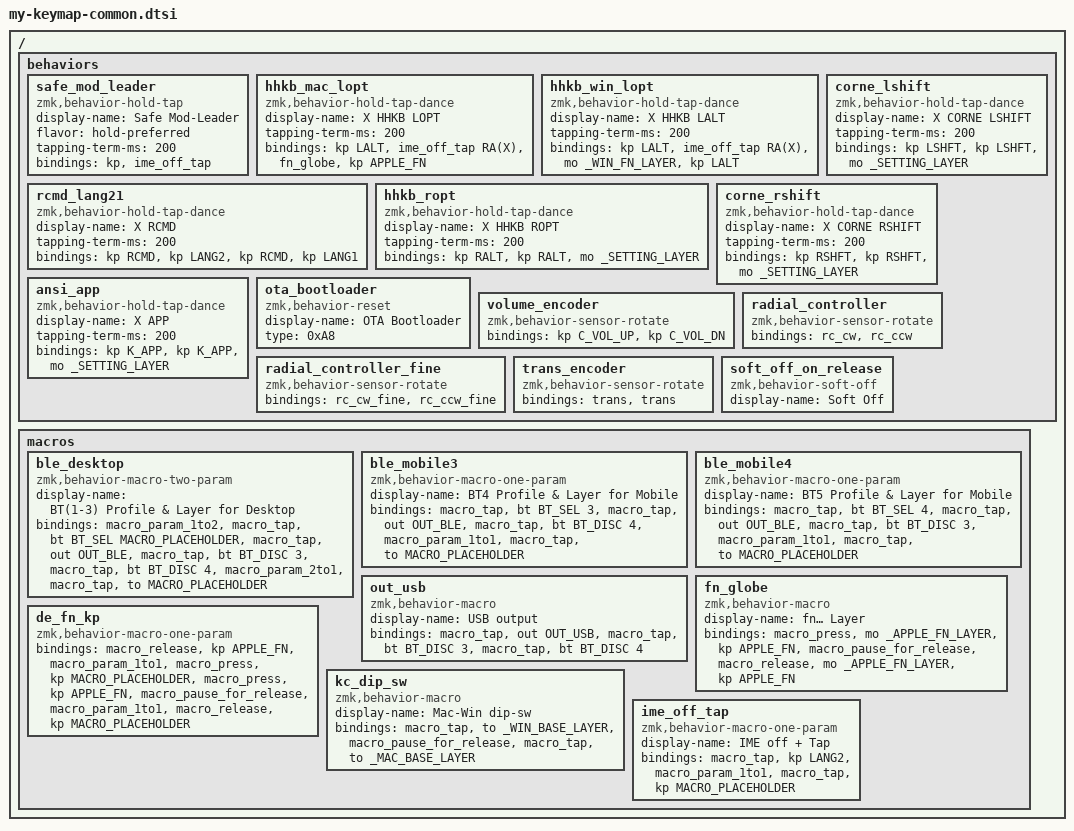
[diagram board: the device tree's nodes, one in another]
#include <behaviors.dtsi>
#include <behaviors/radial_controller.dtsi>
#include <behaviors/beep.dtsi>
#include <dt-bindings/zmk/keys.h>
#include <dt-bindings/zmk/extra_keys.h>
#include <dt-bindings/zmk/outputs.h>
#include <dt-bindings/zmk/bt.h>
#include <dt-bindings/zmk/rgb.h>
#include <dt-bindings/zmk/ext_power.h>
#include <dt-bindings/zmk/beep.h>

#define ______ &trans

// extra key
//--------------------------------------------

// keyboard Page F16
#undef F16
#define F16 EXTRA_KEY_0

// keyboard Page F17
#undef F17
#define F17 EXTRA_KEY_1

// keyboard Page F18
#undef F18
#define F18 EXTRA_KEY_2

// keyboard Page LANG1
#undef LANG1
#define LANG1 EXTRA_KEY_3

// keyboard Page LANG2
#undef LANG2
#define LANG2 EXTRA_KEY_4

// AVT Page keyboardFn
#define APPLE_FN EXTRA_KEY_5

// System Control Page Do Not Disturb
#define SC_DND EXTRA_KEY_6

// common layers
//--------------------------------------------

#define _MAC_BASE_LAYER 0
#define _WIN_BASE_LAYER 1
#define _HHKB_FN_LAYER 2
#define _APPLE_FN_LAYER 3
#define _WIN_FN_LAYER 4
#define _SETTING_LAYER 5
#define _INVERSE_SETTING_LAYER 6
#define _L_THUMB_LAYER 7
#define _R_THUMB_LAYER 8

// key definitions other than kp/trans behavior
//--------------------------------------------

// mod + emacs commands leader key
// hold   mod
// single tap emacs command leader key
#define _MOD_EMACS(mod) &safe_mod_leader mod RA(X)

// mod + spacemacs evil leader key
// hold   mod
// single tap spacemacs leader key
#define _MOD_EVIL(mod) &safe_mod_leader mod RA(M)

// keychron DIP SW
// off: mac base layer
// on: win base layer
#define _DIP_SW &kc_dip_sw

// select mac base layer
#define _MAC &to _MAC_BASE_LAYER

// select win base layer
#define _WIN &to _WIN_BASE_LAYER

// Left Opt on mac base layer for HHKB layout
#define _H_M_LOPT &hhkb_mac_lopt

// Left Opt on mac base layer for HHKB layout
#define _H_W_LOPT &hhkb_win_lopt

// Left Command
#define _LCMD _MOD_EVIL(LCMD)

// Left Opt
#define _LOPT _MOD_EMACS(LALT)

// Right Command
#define _RCMD &rcmd_lang21

// Right Opt for HHKB layout
#define _H_ROPT &hhkb_ropt

// Right Shift for corne keyboard
#define _C_LSHFT &corne_lshift

// Right Shift for corne keyboard
#define _C_RSHFT &corne_rshift

// Left Enter for corne keyboard
// hold: Momentaly L Thumb layer
// tap: ENTER
#define _C_LENT &lt _L_THUMB_LAYER ENTER

// Right SPACE for corne keyboard
// hold: Momentaly R Thumb layer
// tap: ENTER
#define _C_RSPC &lt _R_THUMB_LAYER SPC

// HHKB fn
#define _H_FN &mo _HHKB_FN_LAYER

// Fn/Globe key with momnetary Apple Fn Layer
#define _A_FN &fn_globe

// Fn/Globe key on win base layer
#define _W_FN &mo _WIN_FN_LAYER

// Fn/Globe key on win base layer
#define _X_SET &mo _INVERSE_SETTING_LAYER

// APP key for ANSI/TSANGAN layout
#define _APP &ansi_app

// Spotlight key on apple fn Layer
#define _SPOTLIGHT &de_fn_kp C_AC_SEARCH

// Dictation key on apple fn Layer
#define _DICTATION &de_fn_kp C_VOICE_COMMAND

// Do Not Disturb on apple fn Layer
#define _DND &de_fn_kp SC_DND

// mac power control
//--------------------------------------------
// sscreen lock / sceen saver
#define _MAC_SCLK &kp C_AL_LOCK

// display sleep
// *In sometimes, macos external display dosen't work after KVM switching
//  Press twice this key and then press any key to resolve the issue.
#define _MAC_DSLP &kp RC(RS(K_PWR))

// system sleep
#define _MAC_SSLP &kp RA(RG(K_PWR))

// system sleep or shutdown or restart
#define _MAC_SLRS &kp RC(K_PWR)

// windows power control
//--------------------------------------------
// sscreen lock / sceen saver
#define _WIN_SCLK &kp RG(L)

// soft off
//--------------------------------------------
#define _SOFT_OFF &soft_off_on_release

// ext_power
//--------------------------------------------
#define _EP_ON &ext_power EP_ON
#define _EP_OFF &ext_power EP_OFF

// underglow
//--------------------------------------------
#define _RGB_ON &rgb_ug RGB_ON
#define _RGB_OFF &rgb_ug RGB_OFF
#define _BRI &rgb_ug RGB_BRI
#define _BRD &rgb_ug RGB_BRD
#define _HUI &rgb_ug RGB_HUI
#define _HUD &rgb_ug RGB_HUD
#define _SAI &rgb_ug RGB_SAI
#define _SAD &rgb_ug RGB_SAD
#define _SPI &rgb_ug RGB_SPI
#define _SPD &rgb_ug RGB_SPD
#define _EFF &rgb_ug RGB_EFF
#define _EFR &rgb_ug RGB_EFF

// beep
//--------------------------------------------
#define _BP_ON &beep BEEP_ON
#define _BP_OFF &beep BEEP_OFF
#define _BP_PLY &beep BEEP_PLY

// ZMK STUDIO
//--------------------------------------------
#define _STUDIO &studio_unlock

// Emulate fn/globe shortcut keys for windows
//--------------------------------------------

// F1 : decrease brightness
#define _FN_F1 &kp C_BRI_DN
// F2 : decrease brightness
#define _FN_F2 &kp C_BRI_UP
// F3 : mission cntrol
#define _FN_F3 &kp RG(TAB)
// F4 : spotlight
#define _FN_F4 &kp RA(SPC)
// F5 : dictation, long press for "Hey Siri"
#define _FN_F5 &kp RG(H)
// F6 : do not disturb TODO
#define _FN_F6 &kp F6
// F7 : media prev
#define _FN_F7 &kp C_PREV
// F8 : media play/pause
#define _FN_F8 &kp C_PP
// F9 : media next
#define _FN_F9 &kp C_NEXT
// F10 : mute audio
#define _FN_F10 &kp C_MUTE
// F11 : decrease audio volume
#define _FN_F11 &kp C_VOL_DN
// F12 : increase audio volume
#define _FN_F12 &kp C_VOL_UP
// SPC : Hey Siri -> Copilot
#define _FN_SPC &kp RG(C)
// Q : Quck Notes
#define _FN_Q &kp RG(RA(N))
// E : Emoji & Symbols
#define _FN_E &kp RG(DOT)
// A : Focus Dock
#define _FN_A &kp RG(B)
// F : Full Screen Mode
#define _FN_F &kp F11
// H : Show Desktop
#define _FN_H &kp RG(COMMA)
// C : Show Control Center
#define _FN_C &kp RG(A)
// N : Show Notification
#define _FN_N &kp RG(N)
// M : Focus Menubar
#define _FN_M &kp RALT
// Backspace: Forward delete
#define _FN_BS &kp DEL
// Right : Scroll to the end of a documen
#define _FN_RIGHT &kp KC_END
// Left :  Scroll to the beginning of a document
#define _FN_LEFT &kp KC_HOME
// Down : Scroll down one page
#define _FN_DOWN &kp KC_PGDN
// UP : Scroll up one page
#define _FN_UP &kp KC_PGUP

// select output
//--------------------------------------------

#define _BT_MAC1 &ble_desktop 0 _MAC_BASE_LAYER
#define _BT_MAC2 &ble_desktop 1 _MAC_BASE_LAYER
#define _BT_WIN &ble_desktop 2 _WIN_BASE_LAYER
// for iOS
#define _BT_IOS &ble_mobile3 _MAC_BASE_LAYER
// for Android
#define _BT_AOS &ble_mobile4 _WIN_BASE_LAYER
#define _BT_OFF0 &bt BT_DISC 0
#define _BT_OFF1 &bt BT_DISC 1
#define _BT_OFF2 &bt BT_DISC 2
#define _BT_OFF3 &bt BT_DISC 3
#define _BT_OFF4 &bt BT_DISC 4
#define _BT_CLR &bt BT_CLR
#define _BT_CLR_ALL &bt BT_CLR_ALL
#define _USB &out_usb

// macro / behavior
//--------------------------------------------

/ {
  behaviors {
    // Mod-Tap with IME off
    // leader keys of most application are not work correctly when IME is on.
    /omit-if-no-ref/ safe_mod_leader: safe_mod_leader {
      display-name = "Safe Mod-Leader";
      compatible = "zmk,behavior-hold-tap";
      #binding-cells = <2>;
      flavor = "hold-preferred";
      tapping-term-ms = <200>;
      //          Mod    Tap
      bindings = <&kp>, <&ime_off_tap>;
    };

    // Left Option key on mac base layer for HHKB layout
    // hold -> Left Optoon
    // single tap ->  emacs command leader key
    // tap hold -> APPLE_FN + MO(_MAC_FN_LAYER)
    // double tap -> APPLE_FN
    /omit-if-no-ref/ hhkb_mac_lopt: hhkb_mac_lopt {
      display-name = "X HHKB LOPT";
      compatible = "zmk,behavior-hold-tap-dance";
      #binding-cells = <0>;
      tapping-term-ms = <200>;
      //          hold        tap                   tap-hold     multi-tap
      bindings = <&kp LALT>, <&ime_off_tap RA(X)>, <&fn_globe>, <&kp APPLE_FN>;
    };

    // Left Option key on win base layer for HHKB layout
    // hold -> Left Alt
    // single tap ->  emacs command leader key
    // tap hold -> MO(_WIN_FN_LAYER)
    // double tap -> Left Alt
    /omit-if-no-ref/ hhkb_win_lopt: hhkb_win_lopt {
      display-name = "X HHKB LALT";
      compatible = "zmk,behavior-hold-tap-dance";
      #binding-cells = <0>;
      tapping-term-ms = <200>;
      //          hold        tap                   tap-hold             multi-tap
      bindings = <&kp LALT>, <&ime_off_tap RA(X)>, <&mo _WIN_FN_LAYER>, <&kp LALT>;
    };

    // Right Command key
    // hold -> Right Cmd
    // single tap ->  LANG2(英数)
    // tap hold -> Right CMd
    // double tap -> LANG1(かな)
    /omit-if-no-ref/ rcmd_lang21: rcmd_lang21 {
      display-name = "X RCMD";
      compatible = "zmk,behavior-hold-tap-dance";
      #binding-cells = <0>;
      tapping-term-ms = <200>;
      //          hold       tap          tap-hold     multi-tap
      bindings = <&kp RCMD>, <&kp LANG2>, <&kp RCMD>, <&kp LANG1>;
    };

    // Right Option key for HHKB layout
    // hold -> Right Alt
    // single tap ->  Right Alt
    // tap hold -> MO(_SETTING_LAYER)
    // double tap -> Left Alt
    /omit-if-no-ref/ hhkb_ropt: hhkb_ropt {
      display-name = "X HHKB ROPT";
      compatible = "zmk,behavior-hold-tap-dance";
      #binding-cells = <0>;
      tapping-term-ms = <200>;
      //          hold        tap         tap-hold
      bindings = <&kp RALT>, <&kp RALT>, <&mo _SETTING_LAYER>;
    };

    // Left Shift key for 6c Corne layout
    // hold -> Left Shift
    // single tap ->  Left SHift
    // tap hold -> MO(_SETTING_LAYER)
    // double tap -> Left Shift
    /omit-if-no-ref/ corne_lshift: corne_lshift {
      display-name = "X CORNE LSHIFT";
      compatible = "zmk,behavior-hold-tap-dance";
      #binding-cells = <0>;
      tapping-term-ms = <200>;
      //          hold         tap         tap-hold
      bindings = <&kp LSHFT>, <&kp LSHFT>, <&mo _SETTING_LAYER>;
    };

    // Right Shift key for 6c Corne layout
    // hold -> Right Shift
    // single tap ->  Right SHift
    // tap hold -> MO(_SETTING_LAYER)
    // double tap -> Right Shift
    /omit-if-no-ref/ corne_rshift: corne_rshift {
      display-name = "X CORNE RSHIFT";
      compatible = "zmk,behavior-hold-tap-dance";
      #binding-cells = <0>;
      tapping-term-ms = <200>;
      //          hold         tap          tap-hold
      bindings = <&kp RSHFT>, <&kp RSHFT>, <&mo _SETTING_LAYER>;
    };

    // App key for ANSI layout
    // hold -> App
    // single tap ->  App
    // tap hold -> MO(_SETTING_LAYER)
    // double tap -> App
    /omit-if-no-ref/ ansi_app: ansi_app {
      display-name = "X APP";
      compatible = "zmk,behavior-hold-tap-dance";
      #binding-cells = <0>;
      tapping-term-ms = <200>;
      //          hold         tap          tap-hold
      bindings = <&kp K_APP>, <&kp K_APP>, <&mo _SETTING_LAYER>;
    };

    /omit-if-no-ref/ ota_bootloader: ota_bootloader {
      display-name = "OTA Bootloader";
      compatible = "zmk,behavior-reset";
      type = <0xA8>;
      #binding-cells = <0>;
    };

    /omit-if-no-ref/ volume_encoder: volume_encoder {
      compatible = "zmk,behavior-sensor-rotate";
      #sensor-binding-cells = <0>;
      bindings = <&kp C_VOL_UP>, <&kp C_VOL_DN>;
    };

    // radial controller
    /omit-if-no-ref/ radial_controller: radial_controller {
      compatible = "zmk,behavior-sensor-rotate";
      #sensor-binding-cells = <0>;
      bindings = <&rc_cw>, <&rc_ccw>;
    };

    // radial controller 1/4 fine
    /omit-if-no-ref/ radial_controller_fine: radial_controller_fine {
      compatible = "zmk,behavior-sensor-rotate";
      #sensor-binding-cells = <0>;
      bindings = <&rc_cw_fine>, <&rc_ccw_fine>;
    };

    /omit-if-no-ref/ trans_encoder: trans_encoder {
      compatible = "zmk,behavior-sensor-rotate";
      #sensor-binding-cells = <0>;
      bindings = <&trans>, <&trans>;
    };

    /omit-if-no-ref/ soft_off_on_release: soft_off_on_release {
      display-name = "Soft Off";
      compatible = "zmk,behavior-soft-off";
      #binding-cells = <0>;
    };
  };

  macros {
    // Select BT 0-2 profile & output for Desktop PC
    // param_1: index number(0-2) of bt profile
    // param_2: base layer
    /omit-if-no-ref/ ble_desktop: ble_desktop {
      display-name = "BT(1-3) Profile & Layer for Desktop";
      compatible = "zmk,behavior-macro-two-param";
      #binding-cells = <2>;
      bindings
        = <&macro_param_1to2>
        , <&macro_tap &bt BT_SEL MACRO_PLACEHOLDER>
        , <&macro_tap &out OUT_BLE>
        , <&macro_tap &bt BT_DISC 3> /* disconnect mobile device */
        , <&macro_tap &bt BT_DISC 4> /* disconnect mobile device */
        , <&macro_param_2to1>
        , <&macro_tap &to MACRO_PLACEHOLDER>
        ;
    };

    // Select BT 3 profile & output for Mobile Device
    // param_1: base layer
    /omit-if-no-ref/ ble_mobile3: ble_mobile3 {
      display-name = "BT4 Profile & Layer for Mobile";
      compatible = "zmk,behavior-macro-one-param";
      #binding-cells = <1>;
      bindings
        = <&macro_tap &bt BT_SEL 3>
        , <&macro_tap &out OUT_BLE>
        , <&macro_tap &bt BT_DISC 4> /* disconnect other mobile device */
        , <&macro_param_1to1>
        , <&macro_tap &to MACRO_PLACEHOLDER>
        ;
    };

    // Select BT 4 profile & output for Mobile Device
    // param_1: base layer
    /omit-if-no-ref/ ble_mobile4: ble_mobile4 {
      display-name = "BT5 Profile & Layer for Mobile";
      compatible = "zmk,behavior-macro-one-param";
      #binding-cells = <1>;
      bindings
        = <&macro_tap &bt BT_SEL 4>
        , <&macro_tap &out OUT_BLE>
        , <&macro_tap &bt BT_DISC 3> /* disconnect other mobile device */
        , <&macro_param_1to1>
        , <&macro_tap &to MACRO_PLACEHOLDER>
        ;
    };

    // Select BT 4 profile & output for Mobile Device
    // param_1: base layer
    /omit-if-no-ref/ out_usb: out_usb {
      display-name = "USB output";
      compatible = "zmk,behavior-macro";
      #binding-cells = <0>;
      bindings
        = <&macro_tap &out OUT_USB>
        , <&macro_tap &bt BT_DISC 3> /* disconnect mobile device */
        , <&macro_tap &bt BT_DISC 4> /* disconnect mobile device */
        ;
    };

    // fn_globe key with momentaly apple fn layer
    /omit-if-no-ref/ fn_globe: fn_globe {
      display-name = "fn🌐 Layer";
      compatible = "zmk,behavior-macro";
      #binding-cells = <0>;
      bindings
        = <&macro_press &mo _APPLE_FN_LAYER &kp APPLE_FN>
        , <&macro_pause_for_release>
        , <&macro_release &mo _APPLE_FN_LAYER &kp APPLE_FN>
        ;
    };

    // send key with temporarily releasing fn/globe
    //  *some consumer or system control keys dosen't work with fn/globe key
    // param_1: keycode
    /omit-if-no-ref/ de_fn_kp: de_fn_kp {
      compatible = "zmk,behavior-macro-one-param";
      #binding-cells = <1>;
      bindings
        = <&macro_release &kp APPLE_FN>
        , <&macro_param_1to1>
        , <&macro_press &kp MACRO_PLACEHOLDER>
        , <&macro_press &kp APPLE_FN>
        , <&macro_pause_for_release>
        , <&macro_param_1to1>
        , <&macro_release &kp MACRO_PLACEHOLDER>
        ;
    };

    // keychron dip-sw
    /omit-if-no-ref/ kc_dip_sw: kc_dip_sw {
      display-name = "Mac-Win dip-sw";
      compatible = "zmk,behavior-macro";
      #binding-cells = <0>;
      bindings
        = <&macro_tap &to _WIN_BASE_LAYER>
        , <&macro_pause_for_release>
        , <&macro_tap &to _MAC_BASE_LAYER>
        ;
    };

    // Tap IME-off + kp
    // param_1 keycode
    /omit-if-no-ref/ ime_off_tap: ime_off_tap {
      display-name = "IME off + Tap";
      compatible = "zmk,behavior-macro-one-param";
      #binding-cells = <1>;
      bindings
        = <&macro_tap &kp LANG2>
        , <&macro_param_1to1>
        , <&macro_tap &kp MACRO_PLACEHOLDER>
        ;
    };
  };
};
